AUTOSAR XML (schema 00048)
package /ComponentTypes
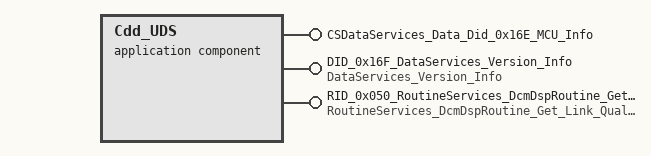
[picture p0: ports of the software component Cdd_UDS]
  application sw component type Cdd_UDS
    provide port CSDataServices_Data_Did_0x16E_MCU_Info: server-com-spec{operation=ReadData, queue-length=1}, provided-interface=CSDataServices_Data_Did_0x16E_MCU_Info
    provide port DID_0x16F_DataServices_Version_Info: provided-interface=DataServices_Version_Info
      provided-com-specs:
        operation=WriteData, queue-length=1
        operation=ConditionCheckRead, queue-length=1
        operation=ReadData, queue-length=1
    provide port RID_0x050_RoutineServices_DcmDspRoutine_Get_Link_Quality_Start: provided-com-specs=[{operation=RequestResults, queue-length=1}, {operation=Start, queue-length=1}], provided-interface=RoutineServices_DcmDspRoutine_Get_Link_Quality_Start
    behavior Cdd_UDS_InternalBehavior
      6 x operation invoked event:
        OIT_Runnable_CSDataServices_Data_Did_0x16E_MCU_Info_ReadData: start-on-event=CSDataServices_Data_Did_0x16E_MCU_Info_ReadData, operation=CSDataServices_Data_Did_0x16E_MCU_Info.ReadData
        OIT_Runnable_DID_0x16F_DataServices_Version_Info_ConditionCheckRead: start-on-event=DID_0x16F_DataServices_Version_Info_ConditionCheckRead, operation=DID_0x16F_DataServices_Version_Info.ConditionCheckRead
        OIT_Runnable_DID_0x16F_DataServices_Version_Info_ReadData: start-on-event=DID_0x16F_DataServices_Version_Info_ReadData, operation=DID_0x16F_DataServices_Version_Info.ReadData
        OIT_Runnable_DID_0x16F_DataServices_Version_Info_WriteData: start-on-event=DID_0x16F_DataServices_Version_Info_WriteData, operation=DID_0x16F_DataServices_Version_Info.WriteData
        OIT_Runnable_RID_0x050_RoutineServices_DcmDspRoutine_Get_Link_Quality_Start_Start: start-on-event=RID_0x050_RoutineServices_DcmDspRoutine_Get_Link_Quality_Start, operation=RID_0x050_RoutineServices_DcmDspRoutine_Get_Link_Quality_Start.Start
        OIT_Runnable_RID_0x050_RoutineServices_DcmDspRoutine_Get_Link_Quality_Start_RequestResults: start-on-event=RID_0x050_RoutineServices_DcmDspRoutine_Get_Link_Quality_Start_RequestResults, operation=RID_0x050_RoutineServices_DcmDspRoutine_Get_Link_Quality_Start.RequestResults
      init event Cdd_UDS_InitEvent: start-on-event=Cdd_UDS_Init
      7 x runnable:
        CSDataServices_Data_Did_0x16E_MCU_Info_ReadData
        DID_0x16F_DataServices_Version_Info_ConditionCheckRead
        DID_0x16F_DataServices_Version_Info_ReadData
        DID_0x16F_DataServices_Version_Info_WriteData
        RID_0x050_RoutineServices_DcmDspRoutine_Get_Link_Quality_Start
        RID_0x050_RoutineServices_DcmDspRoutine_Get_Link_Quality_Start_RequestResults
        Cdd_UDS_Init
  swc implementation Cdd_UDS_Implementation: behavior=Cdd_UDS_InternalBehavior
